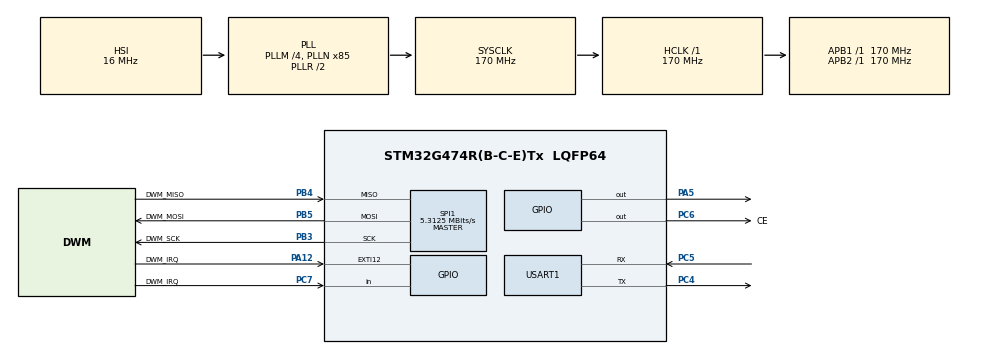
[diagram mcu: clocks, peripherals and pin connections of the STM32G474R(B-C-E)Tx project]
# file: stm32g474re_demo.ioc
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Dma.Request0=USART1_TX
Dma.Request1=USART1_RX
Dma.Request2=SPI1_TX
Dma.Request3=SPI1_RX
Dma.SPI1_RX.3.Direction=DMA_PERIPH_TO_MEMORY
Dma.SPI1_RX.3.EventEnable=DISABLE
Dma.SPI1_RX.3.Instance=DMA1_Channel5
Dma.SPI1_RX.3.MemDataAlignment=DMA_MDATAALIGN_BYTE
Dma.SPI1_RX.3.MemInc=DMA_MINC_ENABLE
Dma.SPI1_RX.3.Mode=DMA_NORMAL
Dma.SPI1_RX.3.PeriphDataAlignment=DMA_PDATAALIGN_BYTE
Dma.SPI1_RX.3.PeriphInc=DMA_PINC_DISABLE
Dma.SPI1_RX.3.Polarity=HAL_DMAMUX_REQ_GEN_RISING
Dma.SPI1_RX.3.Priority=DMA_PRIORITY_HIGH
Dma.SPI1_RX.3.RequestNumber=1
Dma.SPI1_RX.3.SignalID=NONE
Dma.SPI1_RX.3.SyncEnable=DISABLE
Dma.SPI1_RX.3.SyncPolarity=HAL_DMAMUX_SYNC_NO_EVENT
Dma.SPI1_RX.3.SyncRequestNumber=1
Dma.SPI1_RX.3.SyncSignalID=NONE
Dma.SPI1_TX.2.Direction=DMA_MEMORY_TO_PERIPH
Dma.SPI1_TX.2.EventEnable=DISABLE
Dma.SPI1_TX.2.Instance=DMA1_Channel4
Dma.SPI1_TX.2.MemDataAlignment=DMA_MDATAALIGN_BYTE
Dma.SPI1_TX.2.MemInc=DMA_MINC_ENABLE
Dma.SPI1_TX.2.Mode=DMA_NORMAL
Dma.SPI1_TX.2.PeriphDataAlignment=DMA_PDATAALIGN_BYTE
Dma.SPI1_TX.2.PeriphInc=DMA_PINC_DISABLE
Dma.SPI1_TX.2.Polarity=HAL_DMAMUX_REQ_GEN_RISING
Dma.SPI1_TX.2.Priority=DMA_PRIORITY_HIGH
Dma.SPI1_TX.2.RequestNumber=1
Dma.SPI1_TX.2.SignalID=NONE
Dma.SPI1_TX.2.SyncEnable=DISABLE
Dma.SPI1_TX.2.SyncPolarity=HAL_DMAMUX_SYNC_NO_EVENT
Dma.SPI1_TX.2.SyncRequestNumber=1
Dma.SPI1_TX.2.SyncSignalID=NONE
Dma.USART1_RX.1.Direction=DMA_PERIPH_TO_MEMORY
Dma.USART1_RX.1.EventEnable=DISABLE
Dma.USART1_RX.1.Instance=DMA1_Channel3
Dma.USART1_RX.1.MemDataAlignment=DMA_MDATAALIGN_BYTE
Dma.USART1_RX.1.MemInc=DMA_MINC_ENABLE
Dma.USART1_RX.1.Mode=DMA_NORMAL
Dma.USART1_RX.1.PeriphDataAlignment=DMA_PDATAALIGN_BYTE
Dma.USART1_RX.1.PeriphInc=DMA_PINC_DISABLE
Dma.USART1_RX.1.Polarity=HAL_DMAMUX_REQ_GEN_RISING
Dma.USART1_RX.1.Priority=DMA_PRIORITY_HIGH
Dma.USART1_RX.1.RequestNumber=1
Dma.USART1_RX.1.SignalID=NONE
Dma.USART1_RX.1.SyncEnable=DISABLE
Dma.USART1_RX.1.SyncPolarity=HAL_DMAMUX_SYNC_NO_EVENT
Dma.USART1_RX.1.SyncRequestNumber=1
Dma.USART1_RX.1.SyncSignalID=NONE
Dma.USART1_TX.0.Direction=DMA_MEMORY_TO_PERIPH
Dma.USART1_TX.0.EventEnable=DISABLE
Dma.USART1_TX.0.Instance=DMA1_Channel2
Dma.USART1_TX.0.MemDataAlignment=DMA_MDATAALIGN_BYTE
Dma.USART1_TX.0.MemInc=DMA_MINC_ENABLE
Dma.USART1_TX.0.Mode=DMA_NORMAL
Dma.USART1_TX.0.PeriphDataAlignment=DMA_PDATAALIGN_BYTE
Dma.USART1_TX.0.PeriphInc=DMA_PINC_DISABLE
Dma.USART1_TX.0.Polarity=HAL_DMAMUX_REQ_GEN_RISING
Dma.USART1_TX.0.Priority=DMA_PRIORITY_HIGH
Dma.USART1_TX.0.RequestNumber=1
Dma.USART1_TX.0.SignalID=NONE
Dma.USART1_TX.0.SyncEnable=DISABLE
Dma.USART1_TX.0.SyncPolarity=HAL_DMAMUX_SYNC_NO_EVENT
Dma.USART1_TX.0.SyncRequestNumber=1
Dma.USART1_TX.0.SyncSignalID=NONE
IWDG.Prescaler=IWDG_PRESCALER_32
Mcu.Family=STM32G4
Mcu.Name=STM32G474R(B-C-E)Tx
Mcu.Package=LQFP64
NVIC.DMA1_Channel2_IRQn=true\:0\:0\:false\:false\:true\:false\:true\:true
NVIC.DMA1_Channel3_IRQn=true\:0\:0\:false\:false\:true\:false\:true\:true
NVIC.DMA1_Channel4_IRQn=true\:0\:0\:false\:false\:true\:false\:true\:true
NVIC.DMA1_Channel5_IRQn=true\:0\:0\:false\:false\:true\:false\:true\:true
NVIC.EXTI15_10_IRQn=true\:1\:0\:true\:false\:true\:true\:true\:true
NVIC.PriorityGroup=NVIC_PRIORITYGROUP_4
NVIC.USART1_IRQn=true\:0\:0\:false\:false\:true\:true\:true\:true
PA12.GPIO_Label=DWM_IRQ
PA12.GPIO_ModeDefaultEXTI=GPIO_MODE_IT_RISING
PA12.GPIO_PuPd=GPIO_PULLDOWN
PA12.Signal=GPXTI12
PA15.GPIO_Label=DWM_NSS
PA15.Signal=SPI1_NSS
PA5.Signal=GPIO_Output
PB3.GPIO_Label=DWM_SCK
PB3.Mode=Full_Duplex_Master
PB3.Signal=SPI1_SCK
PB4.GPIO_Label=DWM_MISO
PB4.Mode=Full_Duplex_Master
PB4.Signal=SPI1_MISO
PB5.GPIO_Label=DWM_MOSI
PB5.Mode=Full_Duplex_Master
PB5.Signal=SPI1_MOSI
PC4.GPIO_ModeDefaultPP=GPIO_MODE_AF_PP
PC4.GPIO_PuPd=GPIO_NOPULL
PC4.GPIO_Speed=GPIO_SPEED_FREQ_LOW
PC4.Mode=Asynchronous
PC4.Signal=USART1_TX
PC5.GPIO_ModeDefaultPP=GPIO_MODE_AF_PP
PC5.GPIO_PuPd=GPIO_NOPULL
PC5.GPIO_Speed=GPIO_SPEED_FREQ_LOW
PC5.Mode=Asynchronous
PC5.Signal=USART1_RX
PC6.GPIO_Label=CE
PC6.GPIO_PuPd=GPIO_PULLDOWN
PC6.Signal=GPIO_Output
PC7.GPIO_Label=DWM_IRQ
PC7.GPIO_PuPd=GPIO_PULLDOWN
PC7.Signal=GPIO_Input
ProjectManager.HeapSize=0x200
ProjectManager.StackSize=0x400
ProjectManager.TargetToolchain=STM32CubeIDE
RCC.ADC12Freq_Value=170000000
RCC.ADC345Freq_Value=170000000
RCC.AHBFreq_Value=170000000
RCC.APB1Freq_Value=170000000
RCC.APB1TimFreq_Value=170000000
RCC.APB2Freq_Value=170000000
RCC.APB2TimFreq_Value=170000000
RCC.CortexFreq_Value=170000000
RCC.EXTERNAL_CLOCK_VALUE=12288000
RCC.HCLKFreq_Value=170000000
RCC.HSE_VALUE=24000000
RCC.HSI48_VALUE=48000000
RCC.HSI_VALUE=16000000
RCC.LSE_VALUE=32768
RCC.PLLM=RCC_PLLM_DIV4
RCC.PLLN=85
RCC.RTCClockSelection=RCC_RTCCLKSOURCE_LSE
RCC.SYSCLKFreq_VALUE=170000000
RCC.SYSCLKSource=RCC_SYSCLKSOURCE_PLLCLK
RCC.USBFreq_Value=170000000
RCC.VCOOutputFreq_Value=340000000
SPI1.BaudRatePrescaler=SPI_BAUDRATEPRESCALER_32
SPI1.CRCCalculation=SPI_CRCCALCULATION_DISABLE
SPI1.CalculateBaudRate=5.3125 MBits/s
SPI1.DataSize=SPI_DATASIZE_8BIT
SPI1.Direction=SPI_DIRECTION_2LINES
SPI1.Mode=SPI_MODE_MASTER
SPI1.NSSPMode=SPI_NSS_PULSE_DISABLE
SPI1.VirtualType=VM_MASTER
USART1.VirtualMode-Asynchronous=VM_ASYNC
VP_IWDG_VS_IWDG.Mode=IWDG_Activate
VP_SYS_VS_DBSignals.Mode=DisableDeadBatterySignals
board=NUCLEO-G474RE

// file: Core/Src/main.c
/* USER CODE BEGIN Header */
/**
  ******************************************************************************
  * @file           : main.c
  * @brief          : Main program body
  ******************************************************************************
  * @attention
  *
  * <h2><center>&copy; Copyright (c) 2020 STMicroelectronics.
  * All rights reserved.</center></h2>
  *
  * This software component is licensed by ST under BSD 3-Clause license,
  * the "License"; You may not use this file except in compliance with the
  * License. You may obtain a copy of the License at:
  *                        opensource.org/licenses/BSD-3-Clause
  *
  ******************************************************************************
  */
/* USER CODE END Header */
#include "main.h"
#include "dma.h"
#include "iwdg.h"
#include "spi.h"
#include "usart.h"
#include "gpio.h"

void SystemClock_Config(void);

/* USER CODE BEGIN 0 */
/* USER CODE BEGIN PV */
// for test =================
#define BUFFERSIZE                       (COUNTOF(aTxBuffer) - 1)
/* Buffer used for transmission */
uint8_t aTxBuffer[] = "****SPI - Two Boards communication based on DMA **** SPI Message ******** SPI Message ******** SPI Message ****";

/* Buffer used for reception */
uint8_t aRxBuffer[BUFFERSIZE];

//=============================

/* USER CODE END 0 */

int main(void)
{

  /* MCU Configuration--------------------------------------------------------*/

  /* Reset of all peripherals, Initializes the Flash interface and the Systick. */
  HAL_Init();

  /* Configure the system clock */
  SystemClock_Config();

  /* USER CODE BEGIN SysInit */
  hal_comm_bufinit();
  /* USER CODE END SysInit */

  /* Initialize all configured peripherals */
  MX_GPIO_Init();
  MX_DMA_Init();
  MX_USART1_UART_Init();
  MX_SPI1_Init();
  MX_IWDG_Init();
  /* USER CODE BEGIN 2 */
  hal_comm_dmauconf();

#if 0
  //== SPI test ==================================
    if (HAL_SPI_TransmitReceive_DMA(&hspi1, (uint8_t *)aTxBuffer, (uint8_t *)aRxBuffer, BUFFERSIZE) != HAL_OK)
    {
      /* Transfer error in transmission process */
      Error_Handler();
    }

    /*##-2- Wait for the end of the transfer ###################################*/
    /*  Before starting a new communication transfer, you must wait the callback call
        to get the transfer complete confirmation or an error detection.
        For simplicity reasons, this example is just waiting till the end of the
        transfer, but application may perform other tasks while transfer operation
        is ongoing. */
    while (wTransferState == TRANSFER_WAIT)
    {
    }
  //=====================================
#endif
  /* USER CODE END 2 */

  /* Infinite loop */
  while (1)
  {

    /* USER CODE BEGIN 3 */
	  my_sched_loop();
  }
  /* USER CODE END 3 */
}

void SystemClock_Config(void)
{
  RCC_OscInitTypeDef RCC_OscInitStruct = {0};
  RCC_ClkInitTypeDef RCC_ClkInitStruct = {0};
  RCC_PeriphCLKInitTypeDef PeriphClkInit = {0};

  /** Configure the main internal regulator output voltage
  */
  HAL_PWREx_ControlVoltageScaling(PWR_REGULATOR_VOLTAGE_SCALE1_BOOST);
  /** Initializes the RCC Oscillators according to the specified parameters
  * in the RCC_OscInitTypeDef structure.
  */
  RCC_OscInitStruct.OscillatorType = RCC_OSCILLATORTYPE_HSI|RCC_OSCILLATORTYPE_LSI;
  RCC_OscInitStruct.HSIState = RCC_HSI_ON;
  RCC_OscInitStruct.HSICalibrationValue = RCC_HSICALIBRATION_DEFAULT;
  RCC_OscInitStruct.LSIState = RCC_LSI_ON;
  RCC_OscInitStruct.PLL.PLLState = RCC_PLL_ON;
  RCC_OscInitStruct.PLL.PLLSource = RCC_PLLSOURCE_HSI;
  RCC_OscInitStruct.PLL.PLLM = RCC_PLLM_DIV4;
  RCC_OscInitStruct.PLL.PLLN = 85;
  RCC_OscInitStruct.PLL.PLLP = RCC_PLLP_DIV2;
  RCC_OscInitStruct.PLL.PLLQ = RCC_PLLQ_DIV2;
  RCC_OscInitStruct.PLL.PLLR = RCC_PLLR_DIV2;
  if (HAL_RCC_OscConfig(&RCC_OscInitStruct) != HAL_OK)
  {
    Error_Handler();
  }
  /** Initializes the CPU, AHB and APB buses clocks
  */
  RCC_ClkInitStruct.ClockType = RCC_CLOCKTYPE_HCLK|RCC_CLOCKTYPE_SYSCLK
                              |RCC_CLOCKTYPE_PCLK1|RCC_CLOCKTYPE_PCLK2;
  RCC_ClkInitStruct.SYSCLKSource = RCC_SYSCLKSOURCE_PLLCLK;
  RCC_ClkInitStruct.AHBCLKDivider = RCC_SYSCLK_DIV1;
  RCC_ClkInitStruct.APB1CLKDivider = RCC_HCLK_DIV1;
  RCC_ClkInitStruct.APB2CLKDivider = RCC_HCLK_DIV1;

  if (HAL_RCC_ClockConfig(&RCC_ClkInitStruct, FLASH_LATENCY_4) != HAL_OK)
  {
    Error_Handler();
  }
  /** Initializes the peripherals clocks
  */
  PeriphClkInit.PeriphClockSelection = RCC_PERIPHCLK_USART1;
  PeriphClkInit.Usart1ClockSelection = RCC_USART1CLKSOURCE_PCLK2;
  if (HAL_RCCEx_PeriphCLKConfig(&PeriphClkInit) != HAL_OK)
  {
    Error_Handler();
  }
}

void Error_Handler(void)
{
  __disable_irq();
  while (1)
  {
  }
}

/************************ (C) COPYRIGHT STMicroelectronics *****END OF FILE****/
